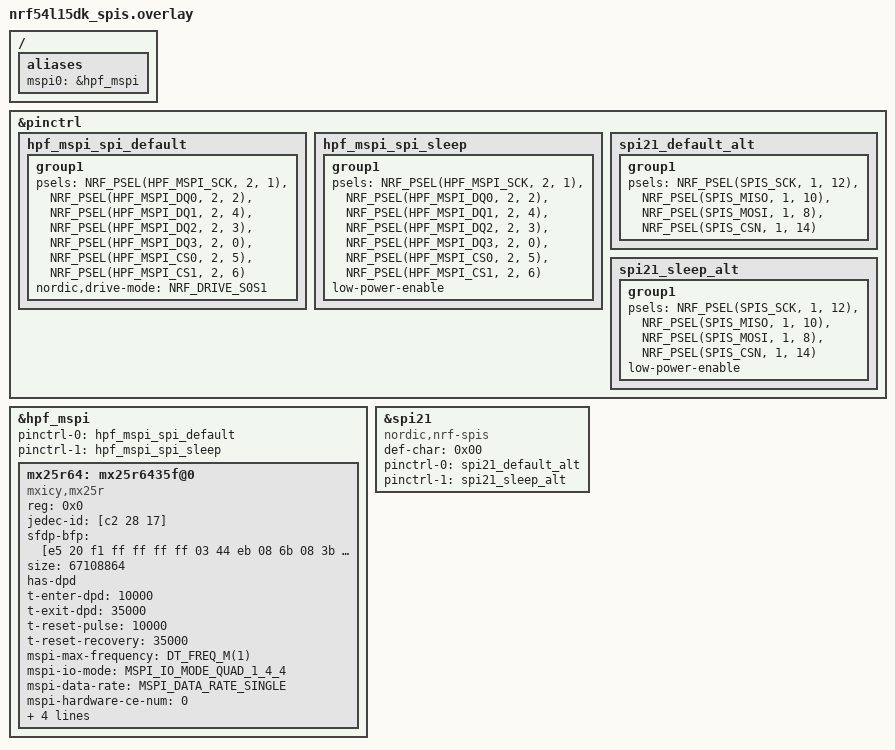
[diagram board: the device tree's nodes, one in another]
/*
 * Copyright (c) 2025 Nordic Semiconductor ASA
 *
 * SPDX-License-Identifier: LicenseRef-Nordic-5-Clause
 */

/ {
	aliases {
		mspi0 = &hpf_mspi;
	};
};

&pinctrl {
	hpf_mspi_spi_default: hpf_mspi_spi_default {
		group1 {
			psels = <NRF_PSEL(HPF_MSPI_SCK, 2, 1)>,
				<NRF_PSEL(HPF_MSPI_DQ0, 2, 2)>,
				<NRF_PSEL(HPF_MSPI_DQ1, 2, 4)>,
				<NRF_PSEL(HPF_MSPI_DQ2, 2, 3)>,
				<NRF_PSEL(HPF_MSPI_DQ3, 2, 0)>,
				<NRF_PSEL(HPF_MSPI_CS0, 2, 5)>,
				<NRF_PSEL(HPF_MSPI_CS1, 2, 6)>;
			nordic,drive-mode = <NRF_DRIVE_S0S1>;
		};
	};

	hpf_mspi_spi_sleep: hpf_mspi_spi_sleep {
		group1 {
			psels = <NRF_PSEL(HPF_MSPI_SCK, 2, 1)>,
				<NRF_PSEL(HPF_MSPI_DQ0, 2, 2)>,
				<NRF_PSEL(HPF_MSPI_DQ1, 2, 4)>,
				<NRF_PSEL(HPF_MSPI_DQ2, 2, 3)>,
				<NRF_PSEL(HPF_MSPI_DQ3, 2, 0)>,
				<NRF_PSEL(HPF_MSPI_CS0, 2, 5)>,
				<NRF_PSEL(HPF_MSPI_CS1, 2, 6)>;
			low-power-enable;
		};
	};

	spi21_default_alt: spi21_default_alt {
		group1 {
			psels = <NRF_PSEL(SPIS_SCK, 1, 12)>,
				<NRF_PSEL(SPIS_MISO, 1, 10)>,
				<NRF_PSEL(SPIS_MOSI, 1, 8)>,
				<NRF_PSEL(SPIS_CSN, 1, 14)>;
		};
	};

	spi21_sleep_alt: spi21_sleep_alt {
		group1 {
			psels = <NRF_PSEL(SPIS_SCK, 1, 12)>,
				<NRF_PSEL(SPIS_MISO, 1, 10)>,
				<NRF_PSEL(SPIS_MOSI, 1, 8)>,
				<NRF_PSEL(SPIS_CSN, 1, 14)>;
			low-power-enable;
		};
	};
};

/delete-node/ &mx25r64;

&hpf_mspi {
	status = "okay";
	pinctrl-0 = <&hpf_mspi_spi_default>;
	pinctrl-1 = <&hpf_mspi_spi_sleep>;

	mx25r64: mx25r6435f@0 {
		compatible = "mxicy,mx25r", "jedec,mspi-nor";
		status = "okay";
		reg = <0x0>;
		jedec-id = [c2 28 17];
		sfdp-bfp = [e5 20 f1 ff ff ff ff 03 44 eb 08 6b 08 3b 04 bb
			    ee ff ff ff ff ff 00 ff ff ff 00 ff 0c 20 0f 52
			    10 d8 00 ff 23 72 f5 00 82 ed 04 cc 44 83 48 44
			    30 b0 30 b0 f7 c4 d5 5c 00 be 29 ff f0 d0 ff ff];
		size = <67108864>;
		has-dpd;
		t-enter-dpd = <10000>;
		t-exit-dpd = <35000>;
		t-reset-pulse = <10000>;
		t-reset-recovery = <35000>;

		mspi-max-frequency = <DT_FREQ_M(1)>;
		mspi-io-mode = "MSPI_IO_MODE_QUAD_1_4_4";
		mspi-data-rate = "MSPI_DATA_RATE_SINGLE";
		mspi-hardware-ce-num = <0>;
		mspi-cpp-mode = "MSPI_CPP_MODE_0";
		mspi-endian = "MSPI_BIG_ENDIAN";
		mspi-ce-polarity = "MSPI_CE_ACTIVE_LOW";

		quad-enable-requirements = "S1B6";
	};
};

dut_spis: &spi21 {
	compatible = "nordic,nrf-spis";
	status = "okay";
	def-char = <0x00>;
	pinctrl-0 = <&spi21_default_alt>;
	pinctrl-1 = <&spi21_sleep_alt>;
	pinctrl-names = "default", "sleep";
	/delete-property/ rx-delay-supported;
	/delete-property/ rx-delay;
};
